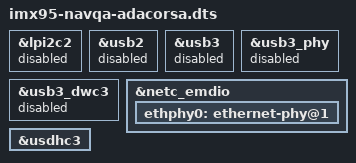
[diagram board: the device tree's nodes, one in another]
// SPDX-License-Identifier: (GPL-2.0+ OR MIT)
/*
 * Copyright 2024 NXP
 */

#include "imx95-navqa.dts"

&lpi2c2 {
        status = "disabled";
};

&usb2 {
	status = "disabled";
};

&usb3 {
	status = "disabled";
};

&usb3_phy {
	status = "disabled";
};

&usb3_dwc3 {
	status = "disabled";
};

&netc_emdio {
        ethphy0: ethernet-phy@1 {
                /delete-property/ reset-gpios;
                /delete-property/ reset-assert-us;
                /delete-property/ reset-deassert-us;
        };
};

&usdhc3 {
	/delete-property/ mmc-pwrseq;
};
